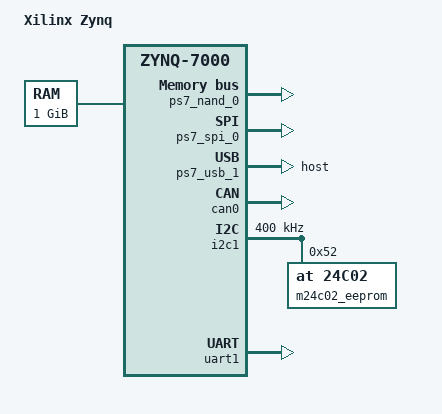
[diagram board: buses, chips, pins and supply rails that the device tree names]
/*
 * Device Tree Generator version: 1.1
 *
 * (C) Copyright 2007-2013 Xilinx, Inc.
 * (C) Copyright 2007-2013 Michal Simek
 * (C) Copyright 2007-2012 PetaLogix Qld Pty Ltd
 *
 * Michal SIMEK <monstr@monstr.eu>
 *
 * CAUTION: This file is automatically generated by libgen.
 * Version: Xilinx EDK 14.5 EDK_P.58f
 *
 */
/dts-v1/;
/include/ "zynq-7000.dtsi"

/ {
	compatible = "xlnx,zynq-zc770-xm011", "xlnx,zynq-7000";
	model = "Xilinx Zynq";

	aliases {
		i2c0 = &i2c1;
		serial0 = &uart1;
		spi0 = &ps7_spi_0;
	};

	chosen {
		bootargs = "console=ttyPS0,115200 root=/dev/ram rw earlyprintk";
		linux,stdout-path = "/amba/serial@e0001000";
	};

	memory@0 {
		device_type = "memory";
		reg = <0x0 0x40000000>;
	};

	amba {
		ps7_smcc_0: ps7-smcc@e000e000 {
			#address-cells = <1>;
			#size-cells = <1>;
			arm,addr25 = <0x0>;
			arm,nor-chip-sel0 = <0x0>;
			arm,nor-chip-sel1 = <0x0>;
			arm,sram-chip-sel0 = <0x0>;
			arm,sram-chip-sel1 = <0x0>;
			clock-names = "memclk", "aclk";
			clocks = <&clkc 11>, <&clkc 44>;
			compatible = "arm,pl353-smc-r2p1";
			interrupt-parent = <&intc>;
			interrupts = <0 18 4>;
			ranges ;
			reg = <0xe000e000 0x1000>;
			ps7_nand_0: ps7-nand@e1000000 {
				arm,nand-cycle-t0 = <0x4>;
				arm,nand-cycle-t1 = <0x4>;
				arm,nand-cycle-t2 = <0x1>;
				arm,nand-cycle-t3 = <0x2>;
				arm,nand-cycle-t4 = <0x2>;
				arm,nand-cycle-t5 = <0x2>;
				arm,nand-cycle-t6 = <0x4>;
				compatible = "arm,pl353-nand-r2p1";
				reg = <0xe1000000 0x1000000>;
				#address-cells = <1>;
				#size-cells = <1>;

				partition@nand-fsbl-uboot {
					label = "nand-fsbl-uboot";
					reg = <0x0 0x100000>;
				};
				partition@nand-linux {
					label = "nand-linux";
					reg = <0x100000 0x500000>;
				};
				partition@nand-device-tree {
					label = "nand-device-tree";
					reg = <0x600000 0x20000>;
				};
				partition@nand-rootfs {
					label = "nand-rootfs";
					reg = <0x620000 0x5E0000>;
				};
				partition@nand-bitstream {
					label = "nand-bitstream";
					reg = <0xC00000 0x400000>;

				};

			} ;
		} ;
		ps7_spi_0: ps7-spi@e0006000 {
			clock-names = "ref_clk", "pclk";
			clocks = <&clkc 25>, <&clkc 34>;
			compatible = "cdns,spi-r1p6";
			interrupt-parent = <&intc>;
			interrupts = <0 26 4>;
			num-cs = <4>;
			is-decoded-cs = <0>;
			reg = <0xe0006000 0x1000>;
		} ;
		ps7_usb_1: ps7-usb@e0003000 {
			clocks = <&clkc 29>;
			compatible = "xlnx,ps7-usb-1.00.a", "xlnx,zynq-usb-1.00.a";
			dr_mode = "host";
			interrupt-parent = <&intc>;
			interrupts = <0 44 4>;
			phy_type = "ulpi";
			reg = <0xe0003000 0x1000>;
		} ;
		ps7_wdt_0: ps7-wdt@f8005000 {
			clocks = <&clkc 45>;
			compatible = "xlnx,zynq-wdt-r1p2";
			device_type = "watchdog";
			interrupt-parent = <&intc>;
			interrupts = <0 9 1>;
			reg = <0xf8005000 0x1000>;
			reset = <0>;
			timeout-sec = <10>;
		} ;
	};
};

&can0 {
	status = "okay";
};

&i2c1 {
	status = "okay";
	clock-frequency = <400000>;

	m24c02_eeprom@52 {
		compatible = "at,24c02";
		reg = <0x52>;
	};
};

&uart1 {
	status = "okay";
};
